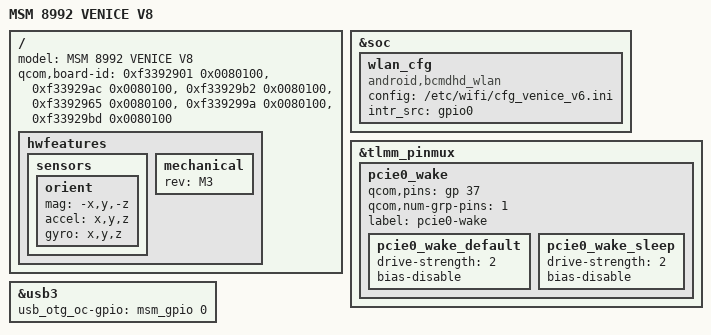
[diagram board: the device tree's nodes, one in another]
/* Copyright (C) 2015 BlackBerry Limited. All rights reserved.
 * Copyright (c) 2014, The Linux Foundation. All rights reserved.
 *
 * This program is free software; you can redistribute it and/or modify
 * it under the terms of the GNU General Public License version 2 and
 * only version 2 as published by the Free Software Foundation.
 *
 * This program is distributed in the hope that it will be useful,
 * but WITHOUT ANY WARRANTY; without even the implied warranty of
 * MERCHANTABILITY or FITNESS FOR A PARTICULAR PURPOSE.  See the
 * GNU General Public License for more details.
 */

/dts-v1/;

#include "msm8992-pm8994-bbry-venice.dtsi"
#include "msm8992-pm8994-bbry-venice-pinmux-v8.dtsi"
#include "msm8992-pm8994-bbry-venice-sensors.dtsi"

/ {
	model = "MSM 8992 VENICE V8";
	qcom,board-id = <0xf3392901 0x0080100>,
			<0xf33929ac 0x0080100>,
			<0xf33929b2 0x0080100>,
			<0xf3392965 0x0080100>,
			<0xf339299a 0x0080100>,
			<0xf33929bd 0x0080100>;

	hwfeatures {
		sensors {
			orient {
				mag = "-x,y,-z";
				accel = "x,y,z";
				gyro = "x,y,z";
			};
		};
		mechanical {
			rev = "M3";
		};
	};

};

&soc {
	wlan_cfg {
		compatible = "android,bcmdhd_wlan";
		/* naming _v6 is to in line with the first "dts" file version with this change */
		config = "/etc/wifi/cfg_venice_v6.ini";
		/* interrupt source is either "pme_l" or "gpio0" */
		intr_src = "gpio0";
	};
};

&tlmm_pinmux {
	/* Override default pull for GPIO_37 (wifi int gpio_0), Venice 804 and later */
	pcie0_wake {
		qcom,pins = <&gp 37>;
		qcom,num-grp-pins = <1>;
		label = "pcie0-wake";
		/* default state */
		/delete-node/ pcie0_wake_default;
		pcie0_wake_default: pcie0_wake_default {
			drive-strength = <2>;
			bias-disable;
		};

		/delete-node/ pcie0_wake_sleep;
		pcie0_wake_sleep: pcie0_wake_sleep {
			drive-strength = <2>;
			bias-disable;
		};
	};
};

&usb3 {
	usb_otg_oc-gpio = <&msm_gpio 0 0x00>;
};
